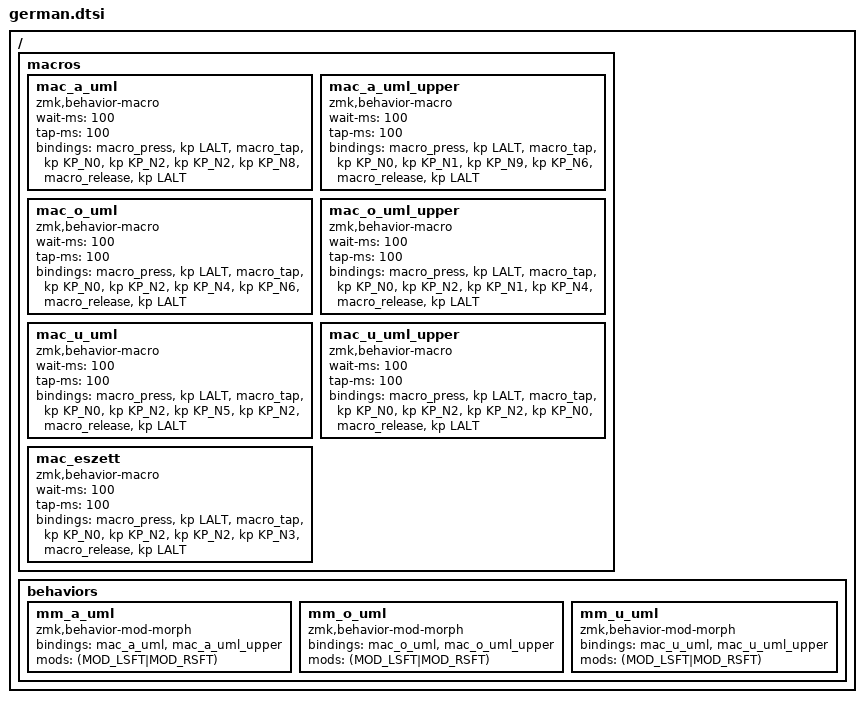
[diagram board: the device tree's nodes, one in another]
/*
 * German — Umlaut + Eszett macros + shift-aware mod-morphs
 *
 * Characters:  ä/Ä  ö/Ö  ü/Ü  ß
 * Method:      Windows Alt Codes (ANSI 0xxx via numpad)
 *              Requires NumLock ON (activate once from Lower layer)
 *
 * Keymap refs: &mm_a_uml &mm_o_uml &mm_u_uml &mac_eszett
 */

/ {
    macros {
        mac_a_uml: mac_a_uml { compatible = "zmk,behavior-macro"; #binding-cells = <0>; wait-ms = <100>; tap-ms = <100>;
            bindings = <&macro_press &kp LALT>, <&macro_tap &kp KP_N0 &kp KP_N2 &kp KP_N2 &kp KP_N8>, <&macro_release &kp LALT>; };
        mac_a_uml_upper: mac_a_uml_upper { compatible = "zmk,behavior-macro"; #binding-cells = <0>; wait-ms = <100>; tap-ms = <100>;
            bindings = <&macro_press &kp LALT>, <&macro_tap &kp KP_N0 &kp KP_N1 &kp KP_N9 &kp KP_N6>, <&macro_release &kp LALT>; };

        mac_o_uml: mac_o_uml { compatible = "zmk,behavior-macro"; #binding-cells = <0>; wait-ms = <100>; tap-ms = <100>;
            bindings = <&macro_press &kp LALT>, <&macro_tap &kp KP_N0 &kp KP_N2 &kp KP_N4 &kp KP_N6>, <&macro_release &kp LALT>; };
        mac_o_uml_upper: mac_o_uml_upper { compatible = "zmk,behavior-macro"; #binding-cells = <0>; wait-ms = <100>; tap-ms = <100>;
            bindings = <&macro_press &kp LALT>, <&macro_tap &kp KP_N0 &kp KP_N2 &kp KP_N1 &kp KP_N4>, <&macro_release &kp LALT>; };

        mac_u_uml: mac_u_uml { compatible = "zmk,behavior-macro"; #binding-cells = <0>; wait-ms = <100>; tap-ms = <100>;
            bindings = <&macro_press &kp LALT>, <&macro_tap &kp KP_N0 &kp KP_N2 &kp KP_N5 &kp KP_N2>, <&macro_release &kp LALT>; };
        mac_u_uml_upper: mac_u_uml_upper { compatible = "zmk,behavior-macro"; #binding-cells = <0>; wait-ms = <100>; tap-ms = <100>;
            bindings = <&macro_press &kp LALT>, <&macro_tap &kp KP_N0 &kp KP_N2 &kp KP_N2 &kp KP_N0>, <&macro_release &kp LALT>; };

        mac_eszett: mac_eszett { compatible = "zmk,behavior-macro"; #binding-cells = <0>; wait-ms = <100>; tap-ms = <100>;
            bindings = <&macro_press &kp LALT>, <&macro_tap &kp KP_N0 &kp KP_N2 &kp KP_N2 &kp KP_N3>, <&macro_release &kp LALT>; };
    };

    behaviors {
        mm_a_uml: mm_a_uml { compatible = "zmk,behavior-mod-morph"; #binding-cells = <0>;
            bindings = <&mac_a_uml>, <&mac_a_uml_upper>; mods = <(MOD_LSFT|MOD_RSFT)>; };
        mm_o_uml: mm_o_uml { compatible = "zmk,behavior-mod-morph"; #binding-cells = <0>;
            bindings = <&mac_o_uml>, <&mac_o_uml_upper>; mods = <(MOD_LSFT|MOD_RSFT)>; };
        mm_u_uml: mm_u_uml { compatible = "zmk,behavior-mod-morph"; #binding-cells = <0>;
            bindings = <&mac_u_uml>, <&mac_u_uml_upper>; mods = <(MOD_LSFT|MOD_RSFT)>; };
    };
};
